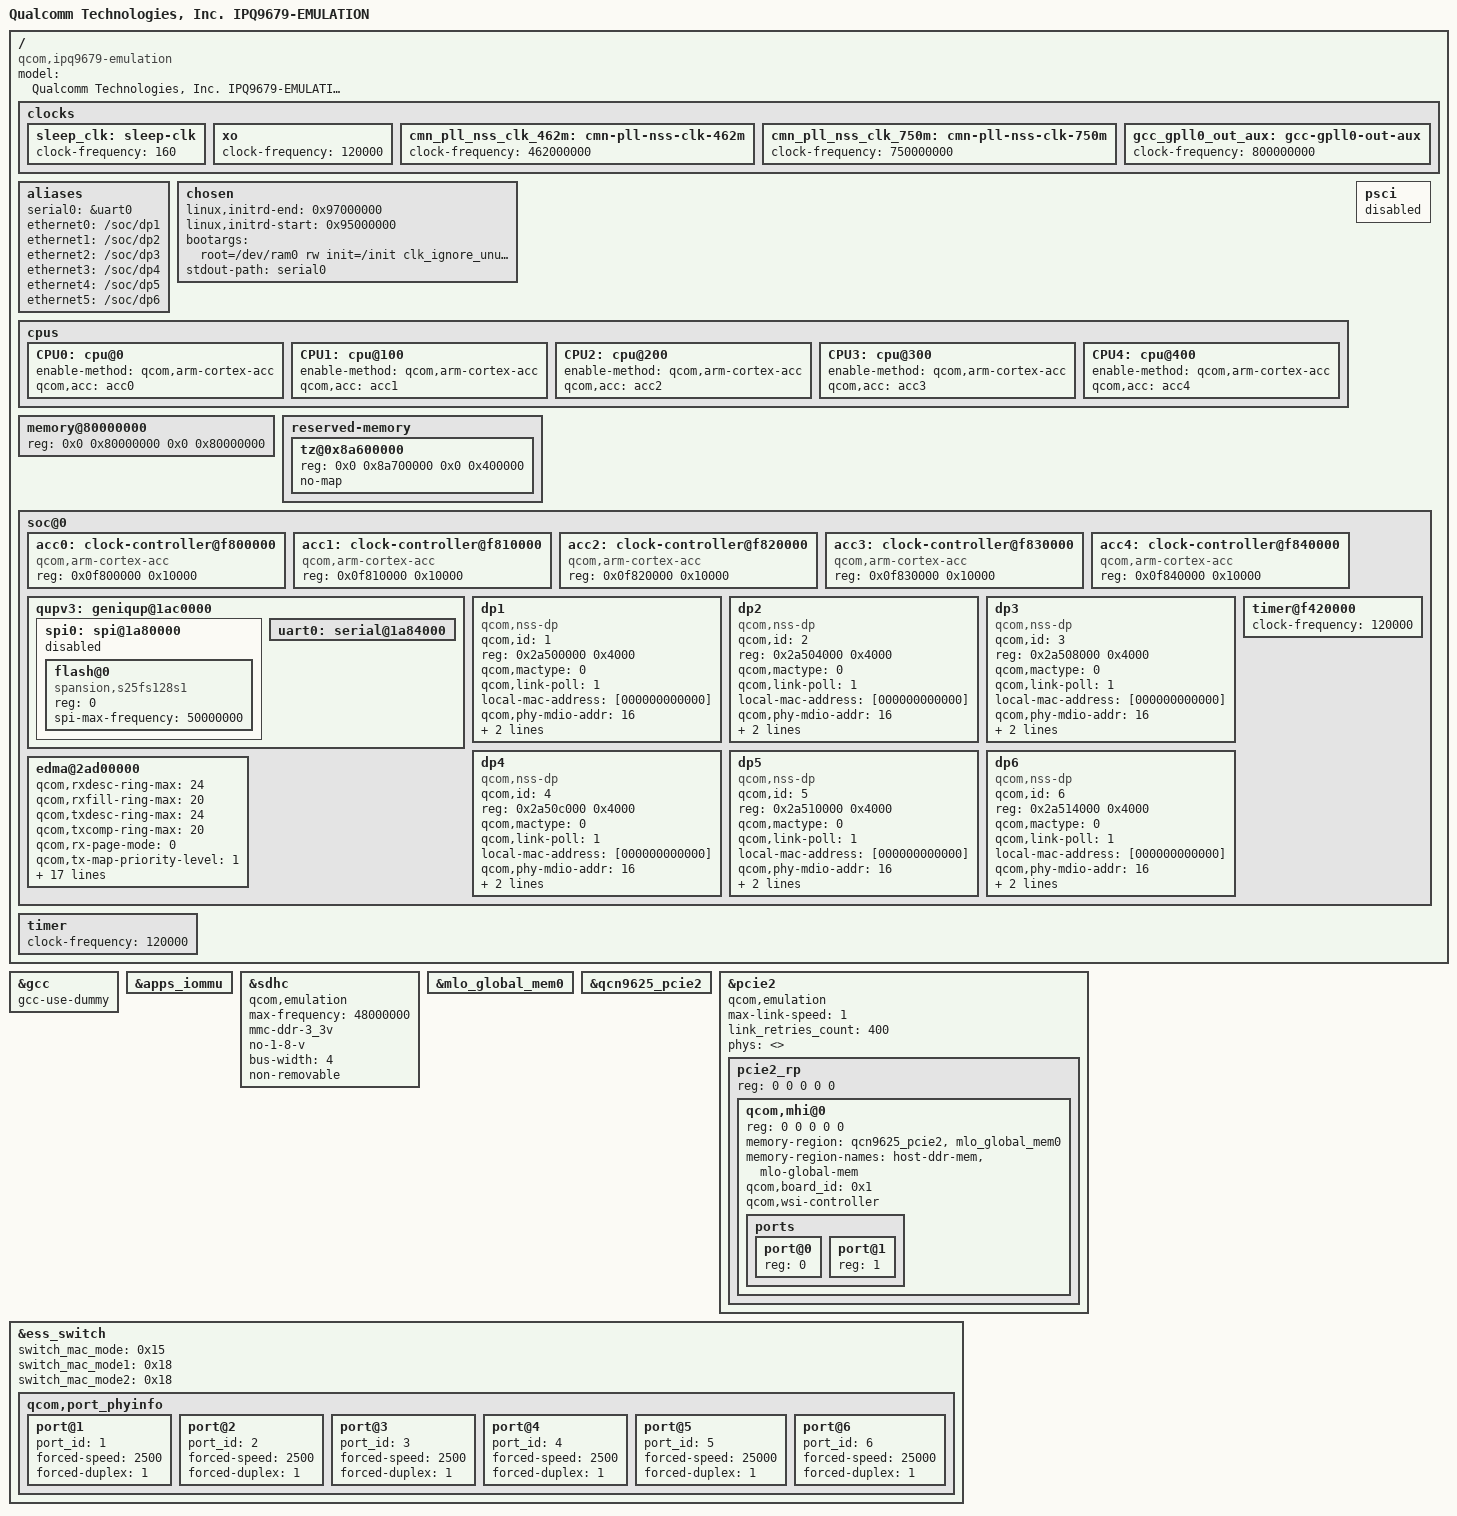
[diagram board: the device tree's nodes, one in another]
// SPDX-License-Identifier: (GPL-2.0+ OR BSD-3-Clause)
/*
 * IPQ9679 Emulation board device tree source
 *
 * Copyright (c) 2020-2021 The Linux Foundation. All rights reserved.
 * Copyright (c) Qualcomm Technologies, Inc. and/or its subsidiaries.
 */

/dts-v1/;

#include "ipq9679.dtsi"
#include "ipq9679-default-memory.dtsi"

/ {
	model = "Qualcomm Technologies, Inc. IPQ9679-EMULATION";
	compatible = "qcom,ipq9679-emulation", "qcom,ipq9679";

	/delete-node/ firmware;
	/delete-node/ ctx-save;

	/* Timer freq for rumi = timer freq / 200 */
	clocks {
		/* sleep-clk freq for rumi = sleep-clk freq (32000) / 200 */
		sleep_clk: sleep-clk {
			clock-frequency = <160>;
		};

		/* xo freq for rumi = xo freq (24000000) / 200 */
		xo: xo {
			clock-frequency = <120000>;
		};

		cmn_pll_nss_clk_462m: cmn-pll-nss-clk-462m {
			clock-frequency = <462000000>;
		};

		cmn_pll_nss_clk_750m: cmn-pll-nss-clk-750m {
			clock-frequency = <750000000>;
		};

		gcc_gpll0_out_aux: gcc-gpll0-out-aux {
			clock-frequency = <800000000>;
		};
	};

	aliases {
		serial0 = &uart0;
		ethernet0 = "/soc/dp1";
		ethernet1 = "/soc/dp2";
		ethernet2 = "/soc/dp3";
		ethernet3 = "/soc/dp4";
		ethernet4 = "/soc/dp5";
		ethernet5 = "/soc/dp6";
	};

	chosen {
		linux,initrd-end = <0x97000000>;
		linux,initrd-start = <0x95000000>;
		bootargs = "root=/dev/ram0 rw init=/init clk_ignore_unused earlycon";
		stdout-path = "serial0";
	};

	cpus: cpus {
		CPU0: cpu@0 {
			enable-method = "qcom,arm-cortex-acc";
			qcom,acc = <&acc0>;
		};

		CPU1: cpu@100 {
			enable-method = "qcom,arm-cortex-acc";
			qcom,acc = <&acc1>;
		};

		CPU2: cpu@200 {
			enable-method = "qcom,arm-cortex-acc";
			qcom,acc = <&acc2>;
		};

		CPU3: cpu@300 {
			enable-method = "qcom,arm-cortex-acc";
			qcom,acc = <&acc3>;
		};

		CPU4: cpu@400 {
			enable-method = "qcom,arm-cortex-acc";
			qcom,acc = <&acc4>;
		};
	};

	memory@80000000 {
		reg = <0x0 0x80000000 0x0 0x80000000>;
	};

	psci {
		status = "disabled";
	};

	reserved-memory {
		#address-cells = <2>;
		#size-cells = <2>;
		ranges;

		tz@0x8a600000 {
			reg = <0x0 0x8a700000 0x0 0x400000>;
			no-map;
		};
	};

	soc@0 {
		acc0: clock-controller@f800000 {
			compatible = "qcom,arm-cortex-acc";
			reg = <0x0f800000 0x10000>;
		};

		acc1: clock-controller@f810000 {
			compatible = "qcom,arm-cortex-acc";
			reg = <0x0f810000 0x10000>;
		};

		acc2:clock-controller@f820000 {
			compatible = "qcom,arm-cortex-acc";
			reg = <0x0f820000 0x10000>;
		};

		acc3:clock-controller@f830000 {
			compatible = "qcom,arm-cortex-acc";
			reg = <0x0f830000 0x10000>;
		};

		acc4:clock-controller@f840000 {
			compatible = "qcom,arm-cortex-acc";
			reg = <0x0f840000 0x10000>;
		};

		qupv3: geniqup@1ac0000 {
			status = "okay";

			spi0: spi@1a80000 {
				status = "disabled";

				flash@0 {
					compatible = "spansion,s25fs128s1", "jedec,spi-nor";
					#address-cells = <1>;
					#size-cells = <1>;
					reg = <0>;
					spi-max-frequency = <50000000>;
				};
			};

			uart0: serial@1a84000 {
				status = "okay";
			};
		};

		dp1 {
			device_type = "network";
			compatible = "qcom,nss-dp";
			qcom,id = <1>;
			reg = <0x2a500000 0x4000>;
			qcom,mactype = <0>;
			qcom,link-poll = <1>;
			local-mac-address = [000000000000];
			qcom,phy-mdio-addr = <16>;
			phy-mode = "usxgmii";
			qcom,ppe-offload-disabled = <1>;
		};

		dp2 {
			device_type = "network";
			compatible = "qcom,nss-dp";
			qcom,id = <2>;
			reg = <0x2a504000 0x4000>;
			qcom,mactype = <0>;
			qcom,link-poll = <1>;
			local-mac-address = [000000000000];
			qcom,phy-mdio-addr = <16>;
			phy-mode = "usxgmii";
			qcom,ppe-offload-disabled = <1>;
		};

		dp3 {
			device_type = "network";
			compatible = "qcom,nss-dp";
			qcom,id = <3>;
			reg = <0x2a508000 0x4000>;
			qcom,mactype = <0>;
			qcom,link-poll = <1>;
			local-mac-address = [000000000000];
			qcom,phy-mdio-addr = <16>;
			phy-mode = "usxgmii";
			qcom,ppe-offload-disabled = <1>;
		};

		dp4 {
			device_type = "network";
			compatible = "qcom,nss-dp";
			qcom,id = <4>;
			reg = <0x2a50c000 0x4000>;
			qcom,mactype = <0>;
			qcom,link-poll = <1>;
			local-mac-address = [000000000000];
			qcom,phy-mdio-addr = <16>;
			phy-mode = "usxgmii";
			qcom,ppe-offload-disabled = <1>;
		};

		dp5 {
			device_type = "network";
			compatible = "qcom,nss-dp";
			qcom,id = <5>;
			reg = <0x2a510000 0x4000>;
			qcom,mactype = <0>;
			qcom,link-poll = <1>;
			local-mac-address = [000000000000];
			qcom,phy-mdio-addr = <16>;
			phy-mode = "usxgmii";
			qcom,ppe-offload-disabled = <1>;
		};

		dp6 {
			device_type = "network";
			compatible = "qcom,nss-dp";
			qcom,id = <6>;
			reg = <0x2a514000 0x4000>;
			qcom,mactype = <0>;
			qcom,link-poll = <1>;
			local-mac-address = [000000000000];
			qcom,phy-mdio-addr = <16>;
			phy-mode = "usxgmii";
			qcom,ppe-offload-disabled = <1>;
		};

		edma@2ad00000{
			qcom,rxdesc-ring-max = <24>;
			qcom,rxfill-ring-max = <20>;
			qcom,txdesc-ring-max = <24>;
			qcom,txcomp-ring-max = <20>;
			qcom,rx-page-mode = <0>;
			qcom,tx-map-priority-level = <1>;
			qcom,rx-map-priority-level = <1>;
			qcom,txdesc-fc-grp-map = <1 2 3 4 5 6>;
			qcom,vp-id = <8>;
			interrupts = <0 294 4>,                 /* Tx complete ring id #0 IRQ info */
				   <0 295 4>,                   /* Tx complete ring id #1 IRQ info */
				   <0 296 4>,                   /* Tx complete ring id #2 IRQ info */
				   <0 297 4>,                   /* Tx complete ring id #3 IRQ info */
				   <0 298 4>,                   /* Tx complete ring id #4 IRQ info */
				   <0 299 4>,                   /* Tx complete ring id #5 IRQ info */
				   <0 300 4>,                   /* Tx complete ring id #6 IRQ info */
				   <0 301 4>,                   /* Tx complete ring id #7 IRQ info */
				   <0 302 4>,                   /* Tx complete ring id #8 IRQ info */
				   <0 303 4>,                   /* Tx complete ring id #9 IRQ info */
				   <0 304 4>,                   /* Tx complete ring id #10 IRQ info */
				   <0 305 4>,                   /* Tx complete ring id #11 IRQ info */
				   <0 306 4>,                   /* Tx complete ring id #12 IRQ info */
				   <0 307 4>,                   /* Tx complete ring id #13 IRQ info */
				   <0 308 4>,                   /* Tx complete ring id #14 IRQ info */
				   <0 309 4>,                   /* Tx complete ring id #15 IRQ info */
				   <0 310 4>,                   /* Tx complete ring id #16 IRQ info */
				   <0 311 4>,                   /* Tx complete ring id #17 IRQ info */
				   <0 312 4>,                   /* Tx complete ring id #18 IRQ info */
				   <0 313 4>,                   /* Tx complete ring id #19 IRQ info */
				   <0 250 4>,                   /* Rx descriptor ring id #0 IRQ info */
				   <0 251 4>,                   /* Rx descriptor ring id #1 IRQ info */
				   <0 252 4>,                   /* Rx descriptor ring id #2 IRQ info */
				   <0 253 4>,                   /* Rx descriptor ring id #3 IRQ info */
				   <0 254 4>,                   /* Rx descriptor ring id #4 IRQ info */
				   <0 255 4>,                   /* Rx descriptor ring id #5 IRQ info */
				   <0 256 4>,                   /* Rx descriptor ring id #6 IRQ info */
				   <0 257 4>,                   /* Rx descriptor ring id #7 IRQ info */
				   <0 258 4>,                   /* Rx descriptor ring id #8 IRQ info */
				   <0 259 4>,                   /* Rx descriptor ring id #9 IRQ info */
				   <0 260 4>,                   /* Rx descriptor ring id #10 IRQ info */
				   <0 261 4>,                   /* Rx descriptor ring id #11 IRQ info */
				   <0 262 4>,			/* Rx descriptor ring id #12 IRQ info */
				   <0 263 4>,                   /* Rx descriptor ring id #13 IRQ info */
				   <0 264 4>,                   /* Rx descriptor ring id #14 IRQ info */
				   <0 265 4>,                   /* Rx descriptor ring id #15 IRQ info */
				   <0 266 4>,                   /* Rx descriptor ring id #16 IRQ info */
				   <0 267 4>,                   /* Rx descriptor ring id #17 IRQ info */
				   <0 268 4>,                   /* Rx descriptor ring id #18 IRQ info */
				   <0 269 4>,                   /* Rx descriptor ring id #19 IRQ info */
				   <0 270 4>,                   /* Rx descriptor ring id #20 IRQ info */
				   <0 271 4>,                   /* Rx descriptor ring id #21 IRQ info */
				   <0 272 4>,                   /* Rx descriptor ring id #22 IRQ info */
				   <0 273 4>,                   /* Rx descriptor ring id #23 IRQ info */
				   <0 274 4>,                   /* Rx fill ring id #0 IRQ info */
				   <0 275 4>,                   /* Rx fill ring id #1 IRQ info */
				   <0 276 4>,                   /* Rx fill ring id #2 IRQ info */
				   <0 277 4>,                   /* Rx fill ring id #3 IRQ info */
				   <0 278 4>,                   /* Rx fill ring id #4 IRQ info */
				   <0 279 4>,                   /* Rx fill ring id #5 IRQ info */
				   <0 280 4>,                   /* Rx fill ring id #6 IRQ info */
				   <0 281 4>,                   /* Rx fill ring id #7 IRQ info */
				   <0 282 4>,                   /* Rx fill ring id #8 IRQ info */
				   <0 283 4>,                   /* Rx fill ring id #9 IRQ info */
				   <0 284 4>,                   /* Rx fill ring id #10 IRQ info */
				   <0 285 4>,                   /* Rx fill ring id #11 IRQ info */
				   <0 286 4>,                   /* Rx fill ring id #12 IRQ info */
				   <0 287 4>,                   /* Rx fill ring id #13 IRQ info */
				   <0 288 4>,                   /* Rx fill ring id #14 IRQ info */
				   <0 289 4>,                   /* Rx fill ring id #15 IRQ info */
				   <0 290 4>,                   /* Rx fill ring id #16 IRQ info */
				   <0 291 4>,                   /* Rx fill ring id #17 IRQ info */
				   <0 292 4>,                   /* Rx fill ring id #18 IRQ info */
				   <0 293 4>;                   /* Rx fill ring id #19 IRQ info */
		};

		/* Timer freq for rumi = timer freq (24000000) / 200 */
		timer@f420000 {
			clock-frequency = <120000>;
		};
	};

	/* Timer freq for rumi = timer freq (24000000) / 200 */
	timer {
		clock-frequency = <120000>;
	};
};

&gcc {
	gcc-use-dummy;
};

&apps_iommu {
	status = "okay";
};

&sdhc {
	qcom,emulation;
	/* override the frequency to 48Mhz for emulation platform */
	max-frequency = <48000000>;
	/* Force 3.3V, because only that will support on emulation platform */
	mmc-ddr-3_3v;
	/* quirk to disable SDR104, SDR50 modes */
	no-1-8-v;
	bus-width = <4>;
	non-removable;
	status = "okay";
};

&mlo_global_mem0 {
	status = "okay";
};

&qcn9625_pcie2 {
	status = "okay";
};

&pcie2 {
	qcom,emulation;
	max-link-speed = <1>;
	link_retries_count = <400>;
	phys = <>;
	phy-names = "";
	status = "okay";

	pcie2_rp {
		reg = <0 0 0 0 0>;

		qcom,mhi@0 {
			reg = <0 0 0 0 0>;
			memory-region = <&qcn9625_pcie2>, <&mlo_global_mem0>;
			memory-region-names = "host-ddr-mem", "mlo-global-mem";
			qcom,board_id = <0x1>;
			qcom,wsi-controller;

			ports {
				#address-cells = <1>;
				#size-cells = <0>;

				port@0 {
					reg = <0>;
				};

				port@1 {
					reg = <1>;
				};
			};
		};
	};
};

&ess_switch {
	switch_mac_mode = <0x15>; /* mac mode for uniphy instance0*/
	switch_mac_mode1 = <0x18>; /* mac mode for uniphy instance1*/
	switch_mac_mode2 = <0x18>; /* mac mode for uniphy instance2*/

	qcom,port_phyinfo {
		port@1 {
			port_id = <1>;
			forced-speed = <2500>;
			forced-duplex = <1>;
		};
		port@2 {
			port_id = <2>;
			forced-speed = <2500>;
			forced-duplex = <1>;
		};
		port@3 {
			port_id = <3>;
			forced-speed = <2500>;
			forced-duplex = <1>;
		};
		port@4 {
			port_id = <4>;
			forced-speed = <2500>;
			forced-duplex = <1>;
		};
		port@5 {
			port_id = <5>;
			forced-speed = <25000>;
			forced-duplex = <1>;
		};
		port@6 {
			port_id = <6>;
			forced-speed = <25000>;
			forced-duplex = <1>;
		};
	};
};
